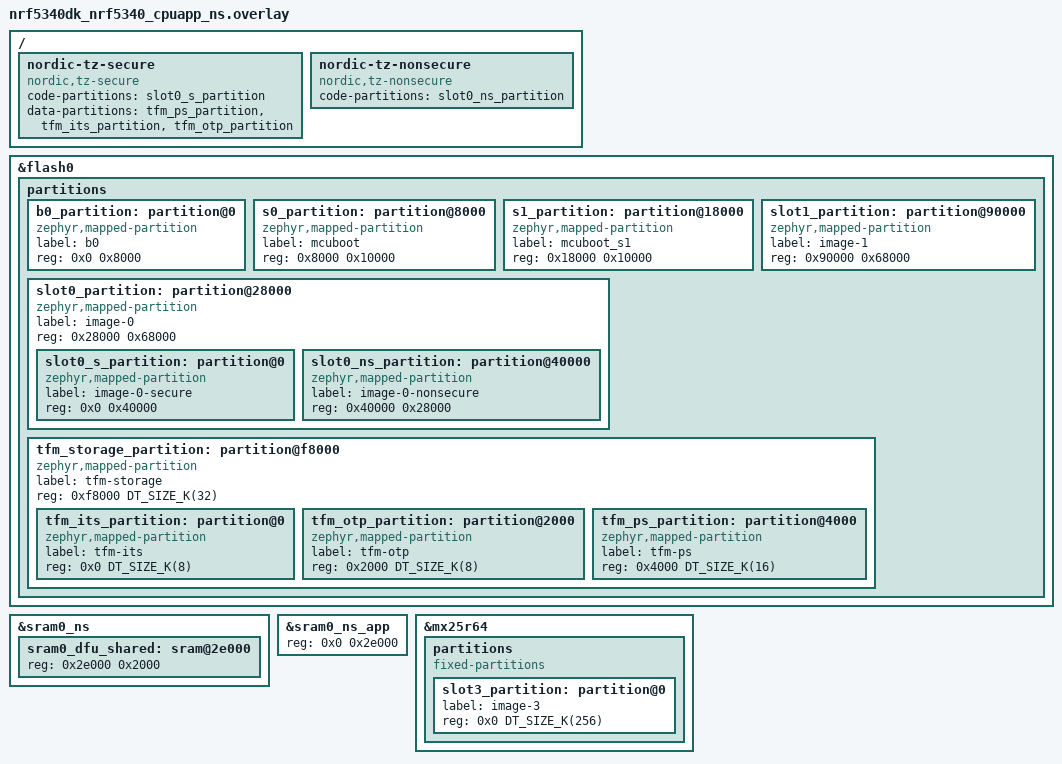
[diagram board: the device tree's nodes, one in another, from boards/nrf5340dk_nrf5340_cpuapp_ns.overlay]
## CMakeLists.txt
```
#
# Copyright (c) 2020 Nordic Semiconductor ASA
#
# SPDX-License-Identifier: LicenseRef-Nordic-5-Clause
#

cmake_minimum_required(VERSION 3.20.0)

find_package(Zephyr REQUIRED HINTS $ENV{ZEPHYR_BASE})

project(tfm_psa_template)

# NORDIC SDK APP START
target_sources(app PRIVATE src/main.c)
# NORDIC SDK APP END


target_include_directories(app PRIVATE
  $<TARGET_PROPERTY:tfm,TFM_BINARY_DIR>/api_ns/interface/include
)
```

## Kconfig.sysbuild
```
#
# Copyright (c) 2024 Nordic Semiconductor
#
# SPDX-License-Identifier: LicenseRef-Nordic-5-Clause
#

config SAMPLE_PROVISIONING_IMAGE
	bool "Build the TF-M provisioning image as a separate, build-only image"
	depends on SOC_SERIES_NRF54L || SOC_SERIES_NRF71
	default y
	help
	  This is the default way to provision the device for this application.

	  This application does not provision the device itself. When this option is
	  enabled, the provisioning_image sample is built alongside the application as
	  an additional, build-only sysbuild image, so it is not programmed by
	  "west flash" and is not included in any merged hex file. Flash and run it
	  before the application to provision the device (write key material and
	  advance the PSA lifecycle state), for example:

	    west flash --recover --domain provisioning_image

	  Because provisioning is a separate image, this also supports split-production
	  flows where provisioning is performed in a secure environment that is
	  separate from where the application firmware is programmed. The provisioning
	  image is built for the secure board target.

	  Disable this option only if you provision the device in another way, such as
	  a standalone build of the provisioning_image sample.

if SOC_SERIES_NRF54L

# nRF54L signs MCUboot with Ed25519 over the full image rather than its hash
# (Pure mode).
config BOOT_SIGNATURE_TYPE_PURE
	default y

# Generate keyfile.json so that "west flash --recover" provisions the NSIB
# Ed25519 public key to CRACEN KMU. Without this, b0 fails validation (-102).
config SECURE_BOOT_GENERATE_DEFAULT_KMU_KEYFILE
	default y if SECURE_BOOT_APPCORE

# Sample development key. Replace for production use.
config SECURE_BOOT_SIGNING_KEY_FILE
	default "../common/keys/nrf54l_nsib_sample_private.pem"

# Placeholder PSA certificate reference. nRF54L does not have a real
# PSA-certified value yet, and Kconfig.tfm only auto-defaults the string for
# nRF9160 and nRF5340. Replace for production use.
config TFM_PSA_CERTIFICATE_REFERENCE_VALUE
	default "0000000000000-00000"

endif # SOC_SERIES_NRF54L

if BOARD_NRF5340DK_NRF5340_CPUAPP_NS

choice NETCORE
	default NETCORE_EMPTY
endchoice

config SECURE_BOOT_NETCORE
	default y

config NETCORE_APP_UPDATE
	default y

config MCUBOOT_APP_SYNC_UPDATEABLE_IMAGES
	default y

config MCUBOOT_USE_ALL_AVAILABLE_RAM
	default y

endif

source "share/sysbuild/Kconfig"
```

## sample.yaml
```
sample:
  description: TF-M PSA Template
  name: TF-M PSA Template
common:
  tags:
    - tfm
    - ci_samples_tfm
  platform_allow:
    - nrf5340dk/nrf5340/cpuapp/ns
    - nrf9151dk/nrf9151/ns
    - nrf9160dk/nrf9160/ns
    - nrf9161dk/nrf9161/ns
    - nrf54l15dk/nrf54l15/cpuapp/ns
    - nrf54lv10dk/nrf54lv10a/cpuapp/ns
    - nrf54lm20dk/nrf54lm20a/cpuapp/ns
    - nrf54lm20dk/nrf54lm20b/cpuapp/ns
  integration_platforms:
    - nrf5340dk/nrf5340/cpuapp/ns
    - nrf9151dk/nrf9151/ns
    - nrf9160dk/nrf9160/ns
    - nrf9161dk/nrf9161/ns
    - nrf54l15dk/nrf54l15/cpuapp/ns
    - nrf54lv10dk/nrf54lv10a/cpuapp/ns
    - nrf54lm20dk/nrf54lm20a/cpuapp/ns
    - nrf54lm20dk/nrf54lm20b/cpuapp/ns
  # The device has to be provisioned by a separate image programmed before the
  # application, so the sample runs from a pytest harness.
  harness: pytest
  harness_config:
    pytest_root:
      - "pytest/test_tfm_psa_template.py"
tests:
  sample.tfm.psa_template:
    sysbuild: true
    extra_args:
      - platform:nrf54l15dk/nrf54l15/cpuapp/ns:SB_CONFIG_SECURE_BOOT_BOOTCONF_ALLOW_UNDERSIZED=y
    tags:
      - ci_build
      - sysbuild
      - ci_samples_tfm
      - pytest
```

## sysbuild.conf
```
#
# Copyright (c) 2023 Nordic Semiconductor
#
# SPDX-License-Identifier: LicenseRef-Nordic-5-Clause
#

SB_CONFIG_BOOTLOADER_MCUBOOT=y
SB_CONFIG_SECURE_BOOT_APPCORE=y
SB_CONFIG_MCUBOOT_MODE_OVERWRITE_ONLY=y
SB_CONFIG_APPROTECT_LOCK=y
SB_CONFIG_SECURE_APPROTECT_LOCK=y
SB_CONFIG_TFM_OTP_PSA_CERTIFICATE_REFERENCE=y
```

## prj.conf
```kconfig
#
# Copyright (c) 2020 Nordic Semiconductor ASA
#
# SPDX-License-Identifier: LicenseRef-Nordic-5-Clause
#

CONFIG_TFM_LOG_LEVEL_SILENCE=n
CONFIG_TFM_SPM_LOG_LEVEL_DEBUG=y
CONFIG_TFM_EXCEPTION_INFO_DUMP=y

CONFIG_TFM_PARTITION_INITIAL_ATTESTATION=y
CONFIG_TFM_NRF_PROVISIONING=y

CONFIG_SECURE_BOOT=y

# Enable mcumgr.
CONFIG_MCUMGR=y
CONFIG_NET_BUF=y
CONFIG_ZCBOR=y
CONFIG_CRC=y
CONFIG_FLASH=y
CONFIG_FLASH_MAP=y
CONFIG_STREAM_FLASH=y
CONFIG_IMG_MANAGER=y
CONFIG_BASE64=y

# Some command handlers require a large stack.
CONFIG_SYSTEM_WORKQUEUE_STACK_SIZE=2304
CONFIG_MAIN_STACK_SIZE=2048

# Enable MCUboot so the application is built as MCUboot-compatible image
CONFIG_BOOTLOADER_MCUBOOT=y

# Required by the `taskstat` command.
CONFIG_THREAD_MONITOR=y

# Support for taskstat command
CONFIG_MCUMGR_GRP_OS_TASKSTAT=y

# Enable statistics and statistic names.
CONFIG_STATS=y
CONFIG_STATS_NAMES=y

# Enable most core commands.
CONFIG_MCUMGR_GRP_IMG=y
CONFIG_MCUMGR_GRP_OS=y
CONFIG_MCUMGR_GRP_STAT=y

# Enable logging
CONFIG_LOG=y
CONFIG_MCUBOOT_UTIL_LOG_LEVEL_WRN=y

# Enable the serial mcumgr transport.
CONFIG_UART_MCUMGR=y
CONFIG_MCUMGR_TRANSPORT_UART=y

# Ensure clean log output
CONFIG_LOG_MODE_IMMEDIATE=y

# Enable TFM isolation level 2
CONFIG_TFM_ISOLATION_LEVEL=2

# Initial Attestation requires RNG
CONFIG_PSA_WANT_GENERATE_RANDOM=y

CONFIG_PSA_WANT_KEY_TYPE_ECC_KEY_PAIR_EXPORT=y

# Optional attestation token fields
CONFIG_TFM_ATTEST_VERIFICATION_SERVICE_URL="verification_url"
```

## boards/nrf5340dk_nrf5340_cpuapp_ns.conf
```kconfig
#
# Copyright (c) 2024 Nordic Semiconductor ASA
#
# SPDX-License-Identifier: LicenseRef-Nordic-5-Clause
#

CONFIG_FPU=y
CONFIG_SOC_NRF53_CPUNET_ENABLE=y
CONFIG_IDENTITY_KEY_TFM=y
```

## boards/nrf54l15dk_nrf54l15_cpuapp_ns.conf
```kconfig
CONFIG_SPI_NOR=n

# Since provisioning is not supported for the nRF54L15 yet,
# we will use dummy provisioning for now.
CONFIG_TFM_NRF_PROVISIONING=n
CONFIG_TFM_DUMMY_PROVISIONING=y
```

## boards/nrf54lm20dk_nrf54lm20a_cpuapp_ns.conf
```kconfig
#
# Copyright (c) 2026 Nordic Semiconductor ASA
#
# SPDX-License-Identifier: LicenseRef-Nordic-5-Clause
#

# The get_fw_info() demo reads the NSIB fw_info of the s0/s1 MCUboot pair, which
# has no non-secure storage backend on nRF54L, so it is compiled out here.
CONFIG_SECURE_BOOT=n
```

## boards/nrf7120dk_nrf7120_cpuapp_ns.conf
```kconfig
#
# Copyright (c) 2026 Nordic Semiconductor ASA
#
# SPDX-License-Identifier: LicenseRef-Nordic-5-Clause
#

# The get_fw_info() demo reads the NSIB fw_info of the s0/s1 MCUboot pair, which
# has no non-secure storage backend on nRF7120, so it is compiled out here.
CONFIG_SECURE_BOOT=n
```

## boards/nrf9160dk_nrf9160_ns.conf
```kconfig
#
# Copyright (c) 2022 Nordic Semiconductor ASA
#
# SPDX-License-Identifier: LicenseRef-Nordic-5-Clause
#

CONFIG_FPU=y
CONFIG_IDENTITY_KEY_TFM=y
```

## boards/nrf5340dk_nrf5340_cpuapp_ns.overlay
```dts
/*
 * Copyright (c) 2024 Nordic Semiconductor ASA
 *
 * SPDX-License-Identifier: LicenseRef-Nordic-5-Clause
 */

/delete-node/ &boot_partition;
/delete-node/ &slot0_partition;
/delete-node/ &slot1_partition;
/delete-node/ &storage_partition;

/delete-node/ &tfm_its_partition;
/delete-node/ &tfm_otp_partition;
/delete-node/ &tfm_ps_partition;

/* s0/s1 must be aligned to the SPU flash block size (0x4000). */
&flash0 {
	partitions {
		b0_partition: partition@0 {
			compatible = "zephyr,mapped-partition";
			label = "b0";
			reg = <0x0 0x8000>;
		};

		s0_partition: partition@8000 {
			compatible = "zephyr,mapped-partition";
			label = "mcuboot";
			reg = <0x8000 0x10000>;
		};

		s1_partition: partition@18000 {
			compatible = "zephyr,mapped-partition";
			label = "mcuboot_s1";
			reg = <0x18000 0x10000>;
		};

		slot0_partition: partition@28000 {
			compatible = "zephyr,mapped-partition";
			label = "image-0";
			reg = <0x28000 0x68000>;
			ranges = <0x0 0x28000 0x68000>;
			#address-cells = <1>;
			#size-cells = <1>;

			slot0_s_partition: partition@0 {
				compatible = "zephyr,mapped-partition";
				label = "image-0-secure";
				reg = <0x0 0x40000>;
			};

			slot0_ns_partition: partition@40000 {
				compatible = "zephyr,mapped-partition";
				label = "image-0-nonsecure";
				reg = <0x40000 0x28000>;
			};
		};

		slot1_partition: partition@90000 {
			compatible = "zephyr,mapped-partition";
			label = "image-1";
			reg = <0x90000 0x68000>;
		};

		tfm_storage_partition: partition@f8000 {
			compatible = "zephyr,mapped-partition";
			label = "tfm-storage";
			reg = <0xf8000 DT_SIZE_K(32)>;
			ranges = <0x0 0xf8000 DT_SIZE_K(32)>;
			#address-cells = <1>;
			#size-cells = <1>;

			tfm_its_partition: partition@0 {
				compatible = "zephyr,mapped-partition";
				label = "tfm-its";
				reg = <0x0 DT_SIZE_K(8)>;
			};

			tfm_otp_partition: partition@2000 {
				compatible = "zephyr,mapped-partition";
				label = "tfm-otp";
				reg = <0x2000 DT_SIZE_K(8)>;
			};

			tfm_ps_partition: partition@4000 {
				compatible = "zephyr,mapped-partition";
				label = "tfm-ps";
				reg = <0x4000 DT_SIZE_K(16)>;
			};
		};
	};
};

/* Place sram0_dfu_shared in sram0_ns so MCUboot does not lock it as part of sram0_s. */
/delete-node/ &sram0_dfu_shared;

&sram0_ns {
	sram0_dfu_shared: sram@2e000 {
		reg = <0x2e000 0x2000>;
	};
};

&sram0_ns_app {
	reg = <0x0 0x2e000>;
};

&mx25r64 {
	partitions {
		compatible = "fixed-partitions";
		#address-cells = <1>;
		#size-cells = <1>;

		slot3_partition: partition@0 {
			label = "image-3";
			reg = <0x0 DT_SIZE_K(256)>;
		};
	};
};

/ {
	/delete-node/ nordic-tz-secure;
	/delete-node/ nordic-tz-nonsecure;

	nordic-tz-secure {
		compatible = "nordic,tz-secure";
		code-partitions = <&slot0_s_partition>;
		data-partitions = <&tfm_ps_partition>,
				  <&tfm_its_partition>,
				  <&tfm_otp_partition>;
	};

	nordic-tz-nonsecure {
		compatible = "nordic,tz-nonsecure";
		code-partitions = <&slot0_ns_partition>;
	};
};
```

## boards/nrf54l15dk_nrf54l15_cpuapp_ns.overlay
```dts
/*
 * Copyright (c) 2026 Nordic Semiconductor ASA
 *
 * SPDX-License-Identifier: LicenseRef-Nordic-5-Clause
 */

/* Replace the default cpuapp_ns partitions with the shared B0 + MCUboot + TF-M
 * table.
 */
/delete-node/ &slot0_s_partition;
/delete-node/ &slot0_ns_partition;
/delete-node/ &tfm_its_partition;
/delete-node/ &tfm_otp_partition;
/delete-node/ &tfm_ps_partition;
/delete-node/ &storage_partition;

#include "../dts/nrf54l15dk_nrf54l15_cpuapp_partitions.dtsi"

/* The inherited nordic-tz descriptors reference the partitions deleted above, so
 * recreate them against the shared table. TF-M and the SoC soc_secure helpers
 * derive the TrustZone-M flash layout from these nodes, so they must mirror the
 * partitions rather than be dropped.
 */
/ {
	/delete-node/ nordic-tz-secure;
	/delete-node/ nordic-tz-nonsecure;

	nordic-tz-secure {
		compatible = "nordic,tz-secure";
		code-partitions = <&slot0_s_partition>;
		data-partitions = <&tfm_ps_partition>,
				  <&tfm_its_partition>,
				  <&tfm_otp_partition>;
	};

	nordic-tz-nonsecure {
		compatible = "nordic,tz-nonsecure";
		code-partitions = <&slot0_ns_partition>;
		data-partitions = <&storage_partition>;
	};
};
```

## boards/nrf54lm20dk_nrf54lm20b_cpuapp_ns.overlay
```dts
/*
 * Copyright (c) 2026 Nordic Semiconductor ASA
 *
 * SPDX-License-Identifier: LicenseRef-Nordic-5-Clause
 */

/* Replace the default cpuapp_ns partitions with the shared B0 + MCUboot + TF-M
 * table.
 */
/delete-node/ &slot0_s_partition;
/delete-node/ &slot0_ns_partition;
/delete-node/ &tfm_its_partition;
/delete-node/ &tfm_otp_partition;
/delete-node/ &tfm_ps_partition;
/delete-node/ &storage_partition;

#include "../dts/nrf54lm20dk_nrf54lm20_cpuapp_partitions.dtsi"

/* The inherited nordic-tz descriptors reference the partitions deleted above, so
 * recreate them against the shared table. TF-M and the SoC soc_secure helpers
 * derive the TrustZone-M flash layout from these nodes, so they must mirror the
 * partitions rather than be dropped.
 */
/ {
	/delete-node/ nordic-tz-secure;
	/delete-node/ nordic-tz-nonsecure;

	nordic-tz-secure {
		compatible = "nordic,tz-secure";
		code-partitions = <&slot0_s_partition>;
		data-partitions = <&tfm_ps_partition>,
				  <&tfm_its_partition>,
				  <&tfm_otp_partition>;
	};

	nordic-tz-nonsecure {
		compatible = "nordic,tz-nonsecure";
		code-partitions = <&slot0_ns_partition>;
		data-partitions = <&storage_partition>;
	};
};
```

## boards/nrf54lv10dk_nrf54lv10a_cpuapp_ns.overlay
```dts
/*
 * Copyright (c) 2026 Nordic Semiconductor ASA
 *
 * SPDX-License-Identifier: LicenseRef-Nordic-5-Clause
 */

/* Replace the default cpuapp_ns partitions with the shared B0 + MCUboot + TF-M
 * table.
 */
/delete-node/ &slot0_s_partition;
/delete-node/ &slot0_ns_partition;
/delete-node/ &tfm_its_partition;
/delete-node/ &tfm_otp_partition;
/delete-node/ &tfm_ps_partition;
/delete-node/ &storage_partition;

#include "../dts/nrf54lv10dk_nrf54lv10a_cpuapp_partitions.dtsi"

/* The inherited nordic-tz descriptors reference the partitions deleted above, so
 * recreate them against the shared table. TF-M and the SoC soc_secure helpers
 * derive the TrustZone-M flash layout from these nodes, so they must mirror the
 * partitions rather than be dropped.
 */
/ {
	/delete-node/ nordic-tz-secure;
	/delete-node/ nordic-tz-nonsecure;

	nordic-tz-secure {
		compatible = "nordic,tz-secure";
		code-partitions = <&slot0_s_partition>;
		data-partitions = <&tfm_ps_partition>,
				  <&tfm_its_partition>,
				  <&tfm_otp_partition>;
	};

	nordic-tz-nonsecure {
		compatible = "nordic,tz-nonsecure";
		code-partitions = <&slot0_ns_partition>;
		data-partitions = <&storage_partition>;
	};
};
```

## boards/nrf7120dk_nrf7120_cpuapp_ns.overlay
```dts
/*
 * Copyright (c) 2026 Nordic Semiconductor ASA
 *
 * SPDX-License-Identifier: LicenseRef-Nordic-5-Clause
 */

/* Replace the default cpuapp_ns partitions with the shared B0 + MCUboot + TF-M
 * table.
 */
/delete-node/ &slot0_s_partition;
/delete-node/ &slot0_ns_partition;
/delete-node/ &tfm_its_partition;
/delete-node/ &tfm_otp_partition;
/delete-node/ &tfm_ps_partition;
/delete-node/ &storage_partition;

#include "../dts/nrf7120dk_nrf7120_cpuapp_partitions.dtsi"
```

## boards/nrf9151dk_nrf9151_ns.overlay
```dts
/*
 * Copyright (c) 2026 Nordic Semiconductor ASA
 *
 * SPDX-License-Identifier: LicenseRef-Nordic-5-Clause
 */

/* Custom partition table providing both NSIB (B0) and an updatable MCUboot
 * in front of a non-minimal TF-M profile with PS / ITS / OTP storage.
 */
/delete-node/ &boot_partition;
/delete-node/ &slot0_partition;
/delete-node/ &slot1_partition;
/delete-node/ &tfm_ps_partition;
/delete-node/ &tfm_its_partition;
/delete-node/ &tfm_otp_partition;
/delete-node/ &storage_partition;

&flash0 {
	/*
	 * 0x0000_0000  B0 (NSIB)                    ( 32 kB)
	 * 0x0000_8000  Primary updatable MCUboot    ( 64 kB)
	 * 0x0001_8000  Secondary updatable MCUboot  ( 64 kB)
	 * 0x0002_8000  Primary image area           (400 kB)
	 *   0x0002_8000  Primary secure image       (128 kB)
	 *   0x0004_8000  Primary non-secure image   (272 kB)
	 * 0x0008_c000  Secondary image area         (400 kB)
	 *   0x0008_c000  Secondary secure image     (128 kB)
	 *   0x000a_c000  Secondary non-secure image (272 kB)
	 * 0x000f_0000  TF-M storage area            ( 32 kB)
	 *   0x000f_0000  TF-M Internal Trusted Stg  (  8 kB)
	 *   0x000f_2000  TF-M OTP / NV counters     (  8 kB)
	 *   0x000f_4000  TF-M Protected Storage     ( 16 kB)
	 * 0x000f_8000  Settings storage             ( 32 kB)
	 */
	partitions {
		ranges;
		#address-cells = <1>;
		#size-cells = <1>;

		b0_partition: partition@0 {
			compatible = "zephyr,mapped-partition";
			label = "b0";
			reg = <0x00000000 0x8000>;
		};

		s0_partition: partition@8000 {
			compatible = "zephyr,mapped-partition";
			label = "mcuboot";
			reg = <0x00008000 0x10000>;
		};

		s1_partition: partition@18000 {
			compatible = "zephyr,mapped-partition";
			label = "mcuboot_s1";
			reg = <0x00018000 0x10000>;
		};

		slot0_partition: partition@28000 {
			compatible = "zephyr,mapped-partition";
			label = "image-0";
			reg = <0x00028000 0x64000>;
			ranges = <0x0 0x00028000 0x64000>;
			#address-cells = <1>;
			#size-cells = <1>;

			slot0_s_partition: partition@0 {
				compatible = "zephyr,mapped-partition";
				label = "image-0-secure";
				reg = <0x00000000 0x20000>;
			};

			slot0_ns_partition: partition@20000 {
				compatible = "zephyr,mapped-partition";
				label = "image-0-nonsecure";
				reg = <0x00020000 0x44000>;
			};
		};

		slot1_partition: partition@8c000 {
			compatible = "zephyr,mapped-partition";
			label = "image-1";
			reg = <0x0008c000 0x64000>;
			ranges = <0x0 0x0008c000 0x64000>;
			#address-cells = <1>;
			#size-cells = <1>;

			slot1_s_partition: partition@0 {
				compatible = "zephyr,mapped-partition";
				label = "image-1-secure";
				reg = <0x00000000 0x20000>;
			};

			slot1_ns_partition: partition@20000 {
				compatible = "zephyr,mapped-partition";
				label = "image-1-nonsecure";
				reg = <0x00020000 0x44000>;
			};
		};

		tfm_storage_partition: partition@f0000 {
			compatible = "zephyr,mapped-partition";
			label = "tfm-storage";
			reg = <0x000f0000 DT_SIZE_K(32)>;
			ranges = <0x0 0x000f0000 DT_SIZE_K(32)>;
			#address-cells = <1>;
			#size-cells = <1>;

			tfm_its_partition: partition@0 {
				compatible = "zephyr,mapped-partition";
				label = "tfm-its";
				reg = <0x0 DT_SIZE_K(8)>;
			};

			tfm_otp_partition: partition@2000 {
				compatible = "zephyr,mapped-partition";
				label = "tfm-otp";
				reg = <0x2000 DT_SIZE_K(8)>;
			};

			tfm_ps_partition: partition@4000 {
				compatible = "zephyr,mapped-partition";
				label = "tfm-ps";
				reg = <0x4000 DT_SIZE_K(16)>;
			};
		};

		storage_partition: partition@f8000 {
			compatible = "zephyr,mapped-partition";
			label = "storage";
			reg = <0x000f8000 DT_SIZE_K(32)>;
		};
	};
};

/* Non-minimal TF-M profile needs the larger secure SRAM layout (88 kB). */
#include <samples/cellular/nrf91_sram_crypto_partitions.dtsi>
```

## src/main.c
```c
/*
 * Copyright (c) 2020 Nordic Semiconductor ASA.
 *
 * SPDX-License-Identifier: LicenseRef-Nordic-5-Clause
 */

#include <zephyr/kernel.h>
#include <zephyr/stats/stats.h>
#include <zephyr/sys/printk.h>
#include <tfm_ns_interface.h>
#include "psa/initial_attestation.h"
#include <psa/crypto.h>
#include <tfm_ioctl_api.h>
#include <tfm_builtin_key_ids.h>
#include <zephyr/storage/flash_map.h>
#define S0_ADDRESS PARTITION_ADDRESS(s0_partition)
#define S1_ADDRESS PARTITION_ADDRESS(s1_partition)
#include <ctype.h>

/* Define an example stats group; approximates seconds since boot. */
STATS_SECT_START(smp_svr_stats)
STATS_SECT_ENTRY(ticks)
STATS_SECT_END;

/* Assign a name to the `ticks` stat. */
STATS_NAME_START(smp_svr_stats)
STATS_NAME(smp_svr_stats, ticks)
STATS_NAME_END(smp_svr_stats);

/* Define an instance of the stats group. */
STATS_SECT_DECL(smp_svr_stats) smp_svr_stats;

void dump_hex_ascii(const uint8_t *data, size_t size)
{
	char ascii[17];
	size_t i, j;

	ascii[16] = '\0';

	printk("\n");
	printk("0  1  2  3  4  5  6  7   8  9  A  B  C  D  E  F\n");

	for (i = 0; i < size; ++i) {
		printk("%02X ", ((unsigned char *)data)[i]);

		ascii[i % 16] = isprint(data[i]) ? data[i] : '.';

		if ((i + 1) % 8 == 0 || i + 1 == size) {
			printk(" ");
			if ((i + 1) % 16 == 0) {
				printk("|  %s\n", ascii);
			} else if ((i + 1) == size) {
				ascii[(i + 1) % 16] = '\0';

				if ((i + 1) % 16 <= 8) {
					printk(" ");
				}

				for (j = (i + 1) % 16; j < 16; ++j) {
					printk("   ");
				}
				printk("|  %s\n", ascii);
			}
		}
	}

	printk("\n");
}

/* get_fw_info() needs CONFIG_FW_INFO (from CONFIG_SECURE_BOOT) and an
 * s1_partition. nRF54L has no non-secure backend for that read path, so
 * CONFIG_SECURE_BOOT is off and this is compiled out there. The rest of the
 * sample works the same on all targets.
 */
#if defined(CONFIG_FW_INFO) && DT_NODE_EXISTS(DT_NODELABEL(s1_partition))
static void get_fw_info_address(uint32_t fw_address)
{
	struct fw_info info;
	int err;

	err = tfm_platform_firmware_info(fw_address, &info);
	if (err) {
		printk("Failed to retrieve fw_info for address 0x%08x\n", fw_address);
		return;
	}

	printk("Magic: 0x");
	for (int i = 0; i < MAGIC_LEN_WORDS; i++) {
		printk("%08x", info.magic[i]);
	}
	printk("\n");

	printk("Total Size: %d\n", info.total_size);
	printk("Size: 0x%08x\n", info.size);
	printk("Version: %u\n", info.version);
	printk("Address: 0x%08x\n", info.address);
	printk("Boot address: 0x%08x\n", info.boot_address);
	printk("Valid: 0x%08x (CONFIG_FW_INFO_VALID_VAL=0x%08x)\n", info.valid,
	       CONFIG_FW_INFO_VALID_VAL);
}

static void get_fw_info(void)
{
	bool s0_active = false;
	int ret;

	ret = tfm_platform_s0_active(S0_ADDRESS, S1_ADDRESS, &s0_active);
	if (ret != 0) {
		printk("Unexpected failure from tfm_platform_s0_active [%d]\n", ret);
	}

	printk("\nFW info S0:\n");
	get_fw_info_address(S0_ADDRESS);

	printk("\nFW info S1:\n");
	get_fw_info_address(S1_ADDRESS);

	printk("\nActive slot: %s\n", s0_active ? "S0" : "S1");
}
#endif /* defined(CONFIG_FW_INFO) && DT_NODE_EXISTS(DT_NODELABEL(s1_partition)) */

static void get_attestation_public_key(void)
{
	static uint8_t pub_key_buf[PSA_KEY_EXPORT_ECC_PUBLIC_KEY_MAX_SIZE(256)];
	size_t pub_key_size;
	psa_status_t status;

	printk("\nRequesting initial attestation public key.\n");

	status = psa_crypto_init();

	if (status) {
		printk("psa_crypto_init (err %d)\n", status);
		return;
	}

	status = psa_export_public_key(TFM_BUILTIN_KEY_ID_IAK, pub_key_buf,
				       sizeof(pub_key_buf), &pub_key_size);

	if (status) {
		printk("psa_export_public_key (err %d)\n", status);
	} else {
		printk("Received initial attestation public key of %zu bytes.\n",
		       pub_key_size);

		dump_hex_ascii(pub_key_buf, pub_key_size);
	}
}

static void get_attestation_token(void)
{
	printk("\n");

	static uint8_t token_buf[PSA_INITIAL_ATTEST_MAX_TOKEN_SIZE];
	int err;

	/* 64-byte challenge, encrypted using the default public key;
	 *
	 * 00 11 22 33 44 55 66 77 88 99 AA BB CC DD EE FF
	 * 00 11 22 33 44 55 66 77 88 99 AA BB CC DD EE FF
	 * 00 11 22 33 44 55 66 77 88 99 AA BB CC DD EE FF
	 * 00 11 22 33 44 55 66 77 88 99 AA BB CC DD EE FF
	 */
	static uint8_t challenge_buf[PSA_INITIAL_ATTEST_CHALLENGE_SIZE_64] = {
		0x00, 0x11, 0x22, 0x33, 0x44, 0x55, 0x66, 0x77, 0x88, 0x99, 0xAA, 0xBB, 0xCC,
		0xDD, 0xEE, 0xFF, 0x00, 0x11, 0x22, 0x33, 0x44, 0x55, 0x66, 0x77, 0x88, 0x99,
		0xAA, 0xBB, 0xCC, 0xDD, 0xEE, 0xFF, 0x00, 0x11, 0x22, 0x33, 0x44, 0x55, 0x66,
		0x77, 0x88, 0x99, 0xAA, 0xBB, 0xCC, 0xDD, 0xEE, 0xFF, 0x00, 0x11, 0x22, 0x33,
		0x44, 0x55, 0x66, 0x77, 0x88, 0x99, 0xAA, 0xBB, 0xCC, 0xDD, 0xEE, 0xFF,
	};

	size_t challenge_buf_size = sizeof(challenge_buf);
	size_t token_buf_size = sizeof(token_buf);
	size_t token_size;

	/* Request the initial attestation token w/the challenge data. */
	printk("Requesting initial attestation token with %u byte challenge.\n",
	       challenge_buf_size);
	err = psa_initial_attest_get_token(challenge_buf, challenge_buf_size, token_buf,
					   token_buf_size, &token_size);

	if (err) {
		printk("psa_initial_attest_get_token (err %d)\n", err);
	} else {
		printk("Received initial attestation token of %zu bytes.\n", token_size);

		dump_hex_ascii(token_buf, token_size);
	}
}

int main(void)
{
	int err;

	err = STATS_INIT_AND_REG(smp_svr_stats, STATS_SIZE_32, "smp_svr_stats");
	if (err < 0) {
		printk("Error initializing stats system [%d]\n", err);
	}

	/* using __TIME__ ensure that a new binary will be built on every
	 * compile which is convenient when testing firmware upgrade.
	 */
	printk("build time: " __DATE__ " " __TIME__ "\n");

#if defined(CONFIG_FW_INFO) && DT_NODE_EXISTS(DT_NODELABEL(s1_partition))
	get_fw_info();
#endif
	get_attestation_public_key();
	get_attestation_token();

	/* The system work queue handles all incoming mcumgr requests.  Let the
	 * main thread idle while the mcumgr server runs.
	 */
	while (1) {
		k_sleep(K_MSEC(1000));
		STATS_INC(smp_svr_stats, ticks);
	}
}
```
